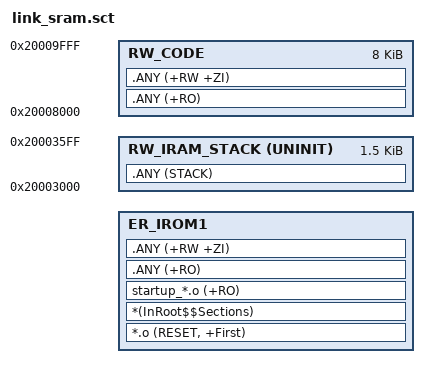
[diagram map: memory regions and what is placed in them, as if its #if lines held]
#! armcc -E --preinclude=..\src\cfg.h

#define SCT_SRAM_BASE     (0x20003600)

#if (SCT_SRAM_STEP)
    #define SCT_SRAM      (SCT_SRAM_BASE + (0x400 * SCT_SRAM_STEP))
#else
    #define SCT_SRAM      (SCT_SRAM_BASE)
#endif
    
#define SCT_SRAM_LEN      (0x20008000 - SCT_SRAM)

LR_IROM1 SCT_SRAM SCT_SRAM_LEN  
{
    ER_IROM1 +0
    {
        *.o (RESET, +First)
        *(InRoot$$Sections)
        startup_*.o (+RO)
        
        #if (SCT_SRAM_STEP < 15)
        .ANY (+RO)
        .ANY (+RW +ZI)
        #endif
    }
    
    RW_IRAM_STACK 0x20003600-0x600 UNINIT 0x600
    {
        .ANY (STACK)
    }
    
    #if (SCT_SRAM_STEP > 14)    
    RW_CODE 0x20008000 0x2000
    {
        .ANY (+RO)
        .ANY (+RW +ZI)
    }
    #endif
}
